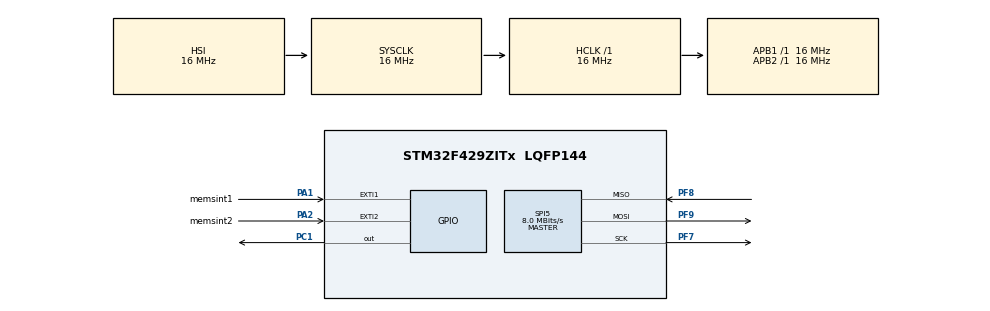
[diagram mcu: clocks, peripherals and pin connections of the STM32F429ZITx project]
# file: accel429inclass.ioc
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Mcu.Family=STM32F4
Mcu.Name=STM32F429ZITx
Mcu.Package=LQFP144
NVIC.EXTI1_IRQn=true\:0\:0\:false\:false\:true\:true\:true\:true
NVIC.EXTI2_IRQn=true\:0\:0\:false\:false\:true\:true\:true\:true
NVIC.PriorityGroup=NVIC_PRIORITYGROUP_4
PA1.GPIO_Label=memsint1
PA1.Signal=GPXTI1
PA13.Mode=Trace_Asynchronous_SW
PA13.Signal=SYS_JTMS-SWDIO
PA14.Mode=Trace_Asynchronous_SW
PA14.Signal=SYS_JTCK-SWCLK
PA2.GPIO_Label=memsint2
PA2.Signal=GPXTI2
PB3.Mode=Trace_Asynchronous_SW
PB3.Signal=SYS_JTDO-SWO
PC1.Signal=GPIO_Output
PF7.Mode=Full_Duplex_Master
PF7.Signal=SPI5_SCK
PF8.Mode=Full_Duplex_Master
PF8.Signal=SPI5_MISO
PF9.Mode=Full_Duplex_Master
PF9.Signal=SPI5_MOSI
ProjectManager.HeapSize=0x200
ProjectManager.StackSize=0x400
ProjectManager.TargetToolchain=STM32CubeIDE
RCC.AHBFreq_Value=16000000
RCC.APB1Freq_Value=16000000
RCC.APB2Freq_Value=16000000
RCC.CortexFreq_Value=16000000
RCC.HSE_VALUE=25000000
RCC.HSI_VALUE=16000000
RCC.LSE_VALUE=32768
RCC.SYSCLKFreq_VALUE=16000000
RCC.VCOOutputFreq_Value=192000000
SPI5.CalculateBaudRate=8.0 MBits/s
SPI5.Direction=SPI_DIRECTION_2LINES
SPI5.Mode=SPI_MODE_MASTER
SPI5.VirtualType=VM_MASTER
board=custom

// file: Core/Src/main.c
/* USER CODE BEGIN Header */
/**
  ******************************************************************************
  * @file           : main.c
  * @brief          : Main program body
  ******************************************************************************
  * @attention
  *
  * Copyright (c) 2022 STMicroelectronics.
  * All rights reserved.
  *
  * This software is licensed under terms that can be found in the LICENSE file
  * in the root directory of this software component.
  * If no LICENSE file comes with this software, it is provided AS-IS.
  *
  ******************************************************************************
  */
/* USER CODE END Header */
#include "main.h"

/* USER CODE BEGIN Includes */
#include "stm32f429i_discovery.h"
#include "stm32f429i_discovery_gyroscope.h"
/* USER CODE END Includes */

 SPI_HandleTypeDef hspi5;

void SystemClock_Config(void);
static void MX_GPIO_Init(void);
static void MX_SPI5_Init(void);
/* USER CODE BEGIN PFP */
float pfData[3];
/* USER CODE END PFP */

/* USER CODE BEGIN 0 */
uint8_t returnid=1;

/* USER CODE END 0 */

int main(void)
{

  /* MCU Configuration--------------------------------------------------------*/

  /* Reset of all peripherals, Initializes the Flash interface and the Systick. */
   HAL_Init();

  /* Configure the system clock */
  SystemClock_Config();

  /* Initialize all configured peripherals */
  MX_GPIO_Init();
  MX_SPI5_Init();
  /* USER CODE BEGIN 2 */
BSP_GYRO_Init();
returnid=BSP_GYRO_ReadID();
  /* USER CODE END 2 */

  /* Infinite loop */
  /* USER CODE BEGIN WHILE */
  while (1)
  {
	  BSP_GYRO_GetXYZ(pfData);
	  HAL_Delay(300);
    /* USER CODE END WHILE */

  }
}

void SystemClock_Config(void)
{
  RCC_OscInitTypeDef RCC_OscInitStruct = {0};
  RCC_ClkInitTypeDef RCC_ClkInitStruct = {0};

  /** Configure the main internal regulator output voltage
  */
  __HAL_RCC_PWR_CLK_ENABLE();
  __HAL_PWR_VOLTAGESCALING_CONFIG(PWR_REGULATOR_VOLTAGE_SCALE3);

  /** Initializes the RCC Oscillators according to the specified parameters
  * in the RCC_OscInitTypeDef structure.
  */
  RCC_OscInitStruct.OscillatorType = RCC_OSCILLATORTYPE_HSI;
  RCC_OscInitStruct.HSIState = RCC_HSI_ON;
  RCC_OscInitStruct.HSICalibrationValue = RCC_HSICALIBRATION_DEFAULT;
  RCC_OscInitStruct.PLL.PLLState = RCC_PLL_NONE;
  if (HAL_RCC_OscConfig(&RCC_OscInitStruct) != HAL_OK)
  {
    Error_Handler();
  }

  /** Initializes the CPU, AHB and APB buses clocks
  */
  RCC_ClkInitStruct.ClockType = RCC_CLOCKTYPE_HCLK|RCC_CLOCKTYPE_SYSCLK
                              |RCC_CLOCKTYPE_PCLK1|RCC_CLOCKTYPE_PCLK2;
  RCC_ClkInitStruct.SYSCLKSource = RCC_SYSCLKSOURCE_HSI;
  RCC_ClkInitStruct.AHBCLKDivider = RCC_SYSCLK_DIV1;
  RCC_ClkInitStruct.APB1CLKDivider = RCC_HCLK_DIV1;
  RCC_ClkInitStruct.APB2CLKDivider = RCC_HCLK_DIV1;

  if (HAL_RCC_ClockConfig(&RCC_ClkInitStruct, FLASH_LATENCY_0) != HAL_OK)
  {
    Error_Handler();
  }
}

static void MX_SPI5_Init(void)
{

  /* SPI5 parameter configuration*/
  hspi5.Instance = SPI5;
  hspi5.Init.Mode = SPI_MODE_MASTER;
  hspi5.Init.Direction = SPI_DIRECTION_2LINES;
  hspi5.Init.DataSize = SPI_DATASIZE_8BIT;
  hspi5.Init.CLKPolarity = SPI_POLARITY_LOW;
  hspi5.Init.CLKPhase = SPI_PHASE_1EDGE;
  hspi5.Init.NSS = SPI_NSS_SOFT;
  hspi5.Init.BaudRatePrescaler = SPI_BAUDRATEPRESCALER_2;
  hspi5.Init.FirstBit = SPI_FIRSTBIT_MSB;
  hspi5.Init.TIMode = SPI_TIMODE_DISABLE;
  hspi5.Init.CRCCalculation = SPI_CRCCALCULATION_DISABLE;
  hspi5.Init.CRCPolynomial = 10;
  if (HAL_SPI_Init(&hspi5) != HAL_OK)
  {
    Error_Handler();
  }

}

static void MX_GPIO_Init(void)
{
  GPIO_InitTypeDef GPIO_InitStruct = {0};

  /* GPIO Ports Clock Enable */
  __HAL_RCC_GPIOF_CLK_ENABLE();
  __HAL_RCC_GPIOC_CLK_ENABLE();
  __HAL_RCC_GPIOA_CLK_ENABLE();
  __HAL_RCC_GPIOB_CLK_ENABLE();

  /*Configure GPIO pin Output Level */
  HAL_GPIO_WritePin(GPIOC, GPIO_PIN_1, GPIO_PIN_RESET);

  /*Configure GPIO pin : PC1 */
  GPIO_InitStruct.Pin = GPIO_PIN_1;
  GPIO_InitStruct.Mode = GPIO_MODE_OUTPUT_PP;
  GPIO_InitStruct.Pull = GPIO_NOPULL;
  GPIO_InitStruct.Speed = GPIO_SPEED_FREQ_LOW;
  HAL_GPIO_Init(GPIOC, &GPIO_InitStruct);

  /*Configure GPIO pins : memsint1_Pin memsint2_Pin */
  GPIO_InitStruct.Pin = memsint1_Pin|memsint2_Pin;
  GPIO_InitStruct.Mode = GPIO_MODE_IT_RISING;
  GPIO_InitStruct.Pull = GPIO_NOPULL;
  HAL_GPIO_Init(GPIOA, &GPIO_InitStruct);

  /* EXTI interrupt init*/
  HAL_NVIC_SetPriority(EXTI1_IRQn, 0, 0);
  HAL_NVIC_EnableIRQ(EXTI1_IRQn);

  HAL_NVIC_SetPriority(EXTI2_IRQn, 0, 0);
  HAL_NVIC_EnableIRQ(EXTI2_IRQn);

}

void Error_Handler(void)
{
  __disable_irq();
  while (1)
  {
  }
}
